# MDR32F8 register map
Vendor: Milandr; File version: 1.0
CPU: CM4 r1p1, little endian, no MPU, no FPU, 3 interrupt priority bits
Registers are 32-bit, read-write, reset 0x0 unless marked. A register's access mark holds for its fields unless they carry their own. Offsets are from the block's base; [hi:lo] are bit positions; {n}, {i} and the like mark numbered series.

## MDR_POWER — POWER
Base 0x40002000
0x00 KEY — Key lock Register
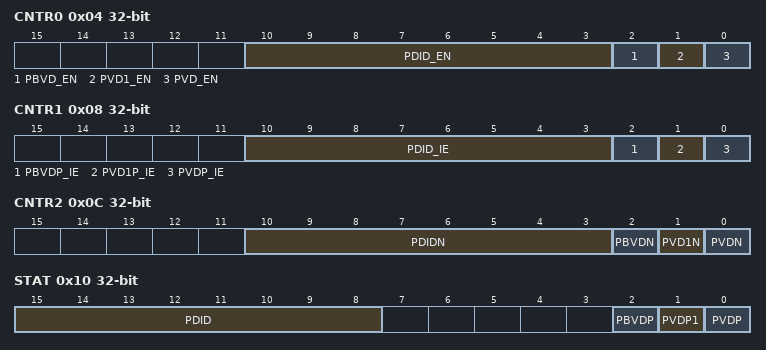
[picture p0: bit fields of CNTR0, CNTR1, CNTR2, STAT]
0x04 CNTR0 — POWER Power Detector Control Register
  [10:3] PDID_EN, [2] PBVD_EN, [1] PVD1_EN, [0] PVD_EN
0x08 CNTR1 — POWER Power Detector Control Register
  [10:3] PDID_IE, [2] PBVDP_IE, [1] PVD1P_IE, [0] PVDP_IE
0x0C CNTR2 — POWER Power Detector Control Register
  [10:3] PDIDN, [2] PBVDN, [1] PVD1N, [0] PVDN
0x10 STAT — POWER Power Detector Status Register
  [15:8] PDID, [2] PBVDP, [1] PVDP1, [0] PVDP
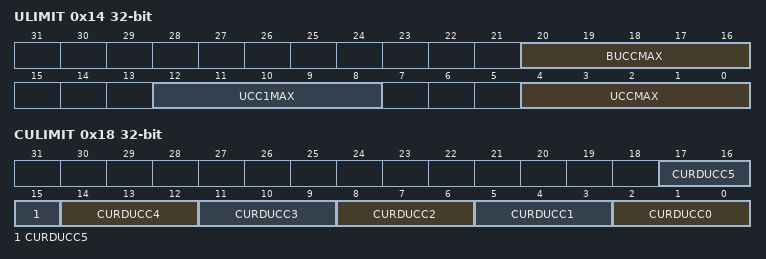
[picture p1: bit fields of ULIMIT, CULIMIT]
0x14 ULIMIT — POWER Power Detector ULIMIT Register
  [20:16] BUCCMAX, [12:8] UCC1MAX, [4:0] UCCMAX
0x18 CULIMIT — POWER Power Detector CULIMIT Register
  [3n+2:3n] CURDUCC{n} (n=0..5)

## MDR_WDT — Watch Dog Timer
Base 0x40004000
0x00 KEY — Key lock Register
0x04 PRL
0x08 EN — EN Register: Counter run - 0x03333
0x0C CNT

## MDR_EBC — External Bus Control
Base 0x40005000
0x00 KEY — Key lock Register
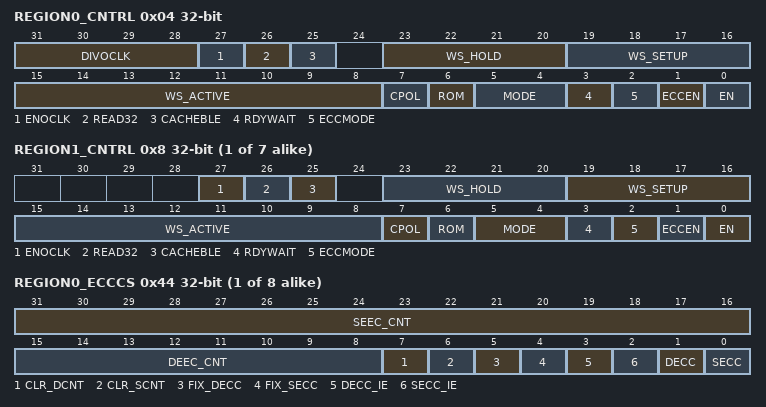
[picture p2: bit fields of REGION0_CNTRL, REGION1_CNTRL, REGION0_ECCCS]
0x04 REGION0_CNTRL
  [31:28] DIVOCLK
  [27] ENOCLK — 0 - OCL OFF, 1 - OCL ON
  [26] READ32
  [25] CACHEBLE — 0 - CACHEBLE OFF, 1 - CACHEBLE ON
  [23:20] WS_HOLD — T = HCLK*(WS_HOLD+1)
  [19:16] WS_SETUP — T = HCLK*(WS_SETUP+1)
  [15:8] WS_ACTIVE — T = HCLK*(WS_ACTIVE+1)
  [7] CPOL — Clock in Active: 0 - Rise, 1 - Fall
  [6] ROM — 0 - RAM, 1 - ROM
  [5:4] MODE — MODE[1:0]: 00 - 32, 01 - 16, 10 - 8, 11 - 64
  [3] RDYWAIT
  [2] ECCMODE — 0 - parallel ECC, 1 - serial ECC
  [1] ECCEN — 0 - ECC OFF, 1 - ECC ON
  [0] EN — 0 - Region OFF, 1 - Region ON
{0x4+4i} REGION{i}_CNTRL (i=1..7)
  [27] ENOCLK — 0 - OCL OFF, 1 - OCL ON
  [26] READ32
  [25] CACHEBLE — 0 - CACHEBLE OFF, 1 - CACHEBLE ON
  [23:20] WS_HOLD — T = HCLK*(WS_HOLD+1)
  [19:16] WS_SETUP — T = HCLK*(WS_SETUP+1)
  [15:8] WS_ACTIVE — T = HCLK*(WS_ACTIVE+1)
  [7] CPOL — Clock in Active: 0 - Rise, 1 - Fall
  [6] ROM — 0 - RAM, 1 - ROM
  [5:4] MODE — MODE[1:0]: 00 - 32, 01 - 16, 10 - 8, 11 - 64
  [3] RDYWAIT
  [2] ECCMODE — 0 - parallel ECC, 1 - serial ECC
  [1] ECCEN — 0 - ECC OFF, 1 - ECC ON
  [0] EN — 0 - Region OFF, 1 - Region ON
{0x24+4i} REGION{i}_ECCBASE (i=0..7)
{0x44+4i} REGION{i}_ECCCS (i=0..7)
  [31:16] SEEC_CNT, [15:8] DEEC_CNT, [7] CLR_DCNT, [6] CLR_SCNT, [5] FIX_DECC, [4] FIX_SECC, [3] DECC_IE, [2] SECC_IE, [1] DECC, [0] SECC
0x94 ECCADR
0x98 ECCDATA
0x9C ECCECC (reset mask 0xFF)

## MDR_OTP — OTP Memory Control
Base 0x40006000
0x00 KEY — Key lock Register
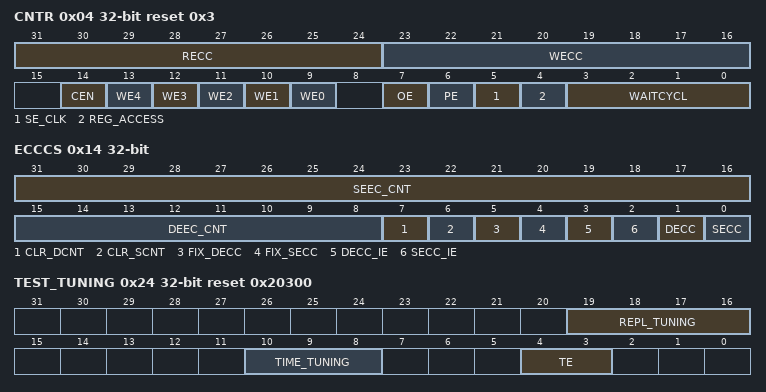
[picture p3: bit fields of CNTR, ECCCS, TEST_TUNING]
0x04 CNTR reset 0x3
  [31:24] RECC
  [23:16] WECC
  [14] CEN — CEN only for RAM (1986VE81T)
  [n+9] WE{n} (n=0..4) — WE only for RAM (1986VE81T)
  [7] OE — OE only for RAM (1986VE81T)
  [6] PE — PE only for OTP (1986VE8T)
  [5] SE_CLK — SE for OTP (1986VE8T), CLK for RAM (1986VE81T)
  [4] REG_ACCESS
  [3:0] WAITCYCL
0x08 ADR
0x0C WDATA
  [31:0] DATA
0x10 RDATA
  [31:0] DATA
0x14 ECCCS
  [31:16] SEEC_CNT, [15:8] DEEC_CNT, [7] CLR_DCNT, [6] CLR_SCNT, [5] FIX_DECC, [4] FIX_SECC, [3] DECC_IE, [2] SECC_IE, [1] DECC, [0] SECC
0x18 ECCADR
0x1C ECCDATA
0x20 ECCECC
  [7:0] ECC
0x24 TEST_TUNING reset 0x20300
  [19:16] REPL_TUNING, [10:8] TIME_TUNING, [4:3] TE

## MDR_RAMD — RAMD Control
Base 0x40008000
Same registers: MDR_ROM 0x40009000
0x00 KEY — Key lock Register
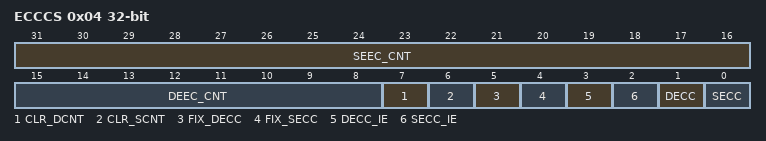
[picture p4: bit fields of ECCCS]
0x04 ECCCS
  [31:16] SEEC_CNT, [15:8] DEEC_CNT, [7] CLR_DCNT, [6] CLR_SCNT, [5] FIX_DECC, [4] FIX_SECC, [3] DECC_IE, [2] SECC_IE, [1] DECC, [0] SECC
0x08 ECCADR
0x0C ECCDATA
0x10 ECCECC
  [7:0] ECC
0x14 TEST_TUNING reset 0x2
  [2:0] TUNE

## MDR_ICACHE — I-BUS Cache Controller
Base 0xE0044000
Same registers: MDR_SCACHE 0x4000B000, MDR_DCACHE 0xE0045000
0x00 KEY — Key lock Register
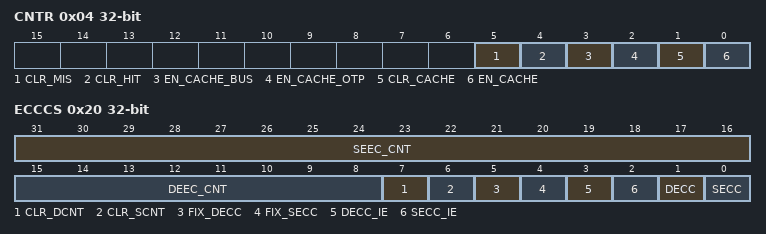
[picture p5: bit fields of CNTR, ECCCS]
0x04 CNTR
  [5] CLR_MIS, [4] CLR_HIT, [3] EN_CACHE_BUS, [2] EN_CACHE_OTP, [1] CLR_CACHE, [0] EN_CACHE
0x08 HIT_CNT
0x0C MISS_CNT
0x20 ECCCS
  [31:16] SEEC_CNT, [15:8] DEEC_CNT, [7] CLR_DCNT, [6] CLR_SCNT, [5] FIX_DECC, [4] FIX_SECC, [3] DECC_IE, [2] SECC_IE, [1] DECC, [0] SECC
0x24 ECCADR
0x28 ECCDATA
0x2C ECCECC
  [7:0] ECC
